# G32R430xx register map
Vendor: Geehy Semiconductor Co., Ltd.; Series: G32R4; File version: 1.0
CPU: CM52 r0p1, little endian, MPU, no FPU, DSP, VTOR, 4 interrupt priority bits
Registers are 32-bit, read-write, reset 0x0 unless marked. A register's access mark holds for its fields unless they carry their own. Offsets are from the block's base; [hi:lo] are bit positions.

## USART1 — Universal synchronous asynchronous receiver transmitter
Base 0x40001400
Same registers: USART2 0x40001800
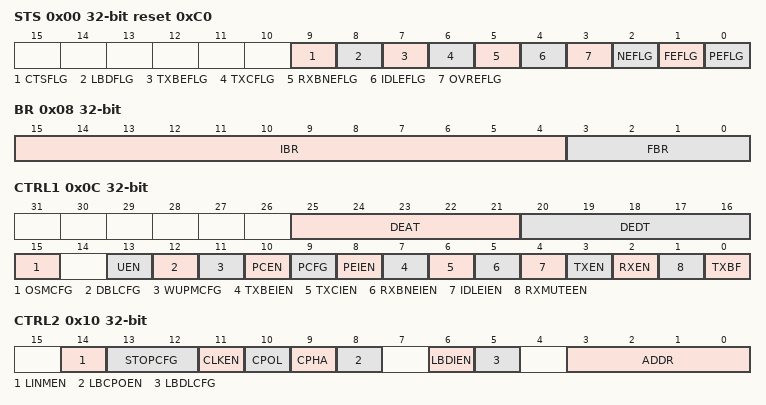
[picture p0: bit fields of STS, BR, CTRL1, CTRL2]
0x00 STS access per field reset 0xC0 — Status register
  [9] CTSFLG rw — CTS flag
  [8] LBDFLG rw — LIN break detection flag
  [7] TXBEFLG ro — Transmit data register empty
  [6] TXCFLG rw — Transmission complete
  [5] RXBNEFLG rw — Read data register not empty
  [4] IDLEFLG ro — IDLE line detected
  [3] OVREFLG ro — Overrun error
  [2] NEFLG ro — Noise detected flag
  [1] FEFLG ro — Framing error
  [0] PEFLG ro — Parity error
0x04 DATA
  [8:0] DATA — Data value
0x08 BR — Baud rate register
  [15:4] IBR — mantissa of USARTDIV
  [3:0] FBR — fraction of USARTDIV
0x0C CTRL1 — Control register 1
  [25:21] DEAT — Driver Enable assertion time
  [20:16] DEDT — Driver Enable deassertion time
  [15] OSMCFG — Oversampling mode
  [13] UEN — USART enable
  [12] DBLCFG — Word length
  [11] WUPMCFG — Wakeup method
  [10] PCEN — Parity control enable
  [9] PCFG — Parity selection
  [8] PEIEN — Parity Error Interrupt Enable
  [7] TXBEIEN — Transmit Buffer Empty Interrupt Enable
  [6] TXCIEN — Transmission complete interrupt enable
  [5] RXBNEIEN — RXNE interrupt enable
  [4] IDLEIEN — IDLE interrupt enable
  [3] TXEN — Transmitter enable
  [2] RXEN — Receiver enable
  [1] RXMUTEEN — Receiver wakeup
  [0] TXBF — Send break
0x10 CTRL2 — Control register 2
  [14] LINMEN — LIN mode enable
  [13:12] STOPCFG — STOP bits
  [11] CLKEN — Clock enable
  [10] CPOL — Clock polarity
  [9] CPHA — Clock phase
  [8] LBCPOEN — Last bit clock pulse
  [6] LBDIEN — LIN break detection interrupt enable
  [5] LBDLCFG — lin break detection length
  [3:0] ADDR — Address of the USART node
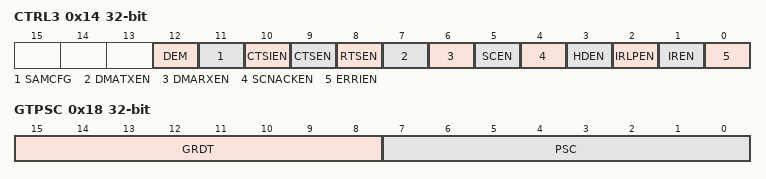
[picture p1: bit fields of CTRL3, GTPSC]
0x14 CTRL3 — Control register 3
  [12] DEM — Driver enable mode
  [11] SAMCFG — Sample Method Configuration
  [10] CTSIEN — CTS interrupt enable
  [9] CTSEN — CTS enable
  [8] RTSEN — RTS enable
  [7] DMATXEN — DMA enable transmitter
  [6] DMARXEN — DMA enable receiver
  [5] SCEN — Smartcard mode enable
  [4] SCNACKEN — Smartcard NACK enable
  [3] HDEN — Half-duplex selection
  [2] IRLPEN — IrDA low-power
  [1] IREN — IrDA mode enable
  [0] ERRIEN — Error interrupt enable
0x18 GTPSC — Guard time and prescaler register
  [15:8] GRDT — Guard time value
  [7:0] PSC — Prescaler value

## I2C1 — Inter integrated circuit 1
Base 0x40001C00
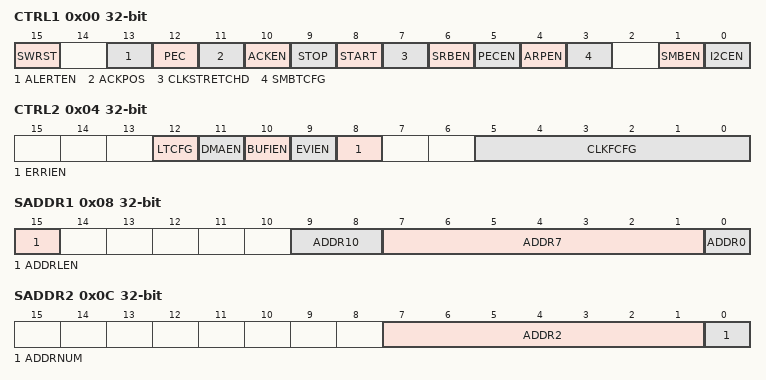
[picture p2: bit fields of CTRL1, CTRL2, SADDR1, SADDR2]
0x00 CTRL1 — Control register 1
  [15] SWRST — Software reset
  [13] ALERTEN — SMBus alert
  [12] PEC — Packet error checking
  [11] ACKPOS — Acknowledge/PEC Position (for data reception)
  [10] ACKEN — Acknowledge enable
  [9] STOP — Stop generation
  [8] START — Start generation
  [7] CLKSTRETCHD — Clock stretching disable (Slave mode)
  [6] SRBEN — General call enable
  [5] PECEN — PEC enable
  [4] ARPEN — ARP enable
  [3] SMBTCFG — SMBus type
  [1] SMBEN — SMBus mode
  [0] I2CEN — I2C enable
0x04 CTRL2 — Control register 2
  [12] LTCFG — DMA last transfer
  [11] DMAEN — DMA requests enable
  [10] BUFIEN — Buffer interrupt enable
  [9] EVIEN — Event interrupt enable
  [8] ERRIEN — Error interrupt enable
  [5:0] CLKFCFG — I2C clock frequency
0x08 SADDR1 — Own address register 1
  [15] ADDRLEN — Addressing mode (slave mode)
  [9:8] ADDR10 — Interface address
  [7:1] ADDR7 — Interface address
  [0] ADDR0 — Interface address
0x0C SADDR2 — Own address register 2
  [7:1] ADDR2 — Interface address
  [0] ADDRNUM — Slave Address Number Configure
0x10 DATA
  [7:0] DATA — 8-bit data register
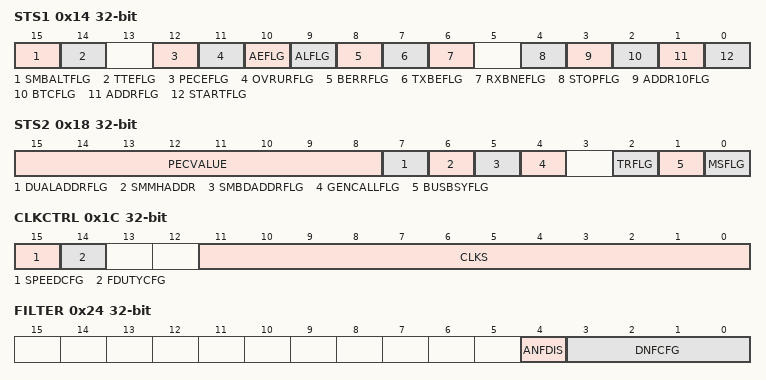
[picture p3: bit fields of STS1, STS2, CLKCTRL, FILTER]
0x14 STS1 access per field — Status register 1
  [15] SMBALTFLG rw — SMBus alert
  [14] TTEFLG rw — Timeout or Tlow error
  [12] PECEFLG rw — PEC Error in reception
  [11] OVRURFLG rw — Overrun/Underrun
  [10] AEFLG rw — Acknowledge failure
  [9] ALFLG rw — Arbitration lost (master mode)
  [8] BERRFLG rw — Bus error
  [7] TXBEFLG ro — Data register empty (transmitters)
  [6] RXBNEFLG ro — Data register not empty (receivers)
  [4] STOPFLG ro — Stop detection (slave mode)
  [3] ADDR10FLG ro — 10-bit header sent (Master mode)
  [2] BTCFLG ro — Byte transfer finished
  [1] ADDRFLG ro — Address sent (master mode)/matched (slave mode)
  [0] STARTFLG ro — Start bit (Master mode)
0x18 STS2 ro — Status register 2
  [15:8] PECVALUE — Save Packet Error Checking Value
  [7] DUALADDRFLG — Dual flag (Slave mode)
  [6] SMMHADDR — SMBus host header (Slave mode)
  [5] SMBDADDRFLG — SMBus device default address (Slave mode)
  [4] GENCALLFLG — General call address (Slave mode)
  [2] TRFLG — Transmitter/receiver
  [1] BUSBSYFLG — Bus busy
  [0] MSFLG — Master Slave Mode Flag
0x1C CLKCTRL — Clock control register
  [15] SPEEDCFG — Master Mode Speed Configure
  [14] FDUTYCFG — Fast mode duty cycle
  [11:0] CLKS — Clock control register in Fast/Standard mode (Master mode)
0x20 RISETMAX reset 0x2 — Maximum Rise Time register
  [5:0] RISETMAX — Maximum rise time in Fast/Standard mode (Master mode)
0x24 FILTER — Filter control register
  [4] ANFDIS — Analog Noise Filter Disable
  [3:0] DNFCFG — Digitial Noise Filter Filtering Capabitity Configure
